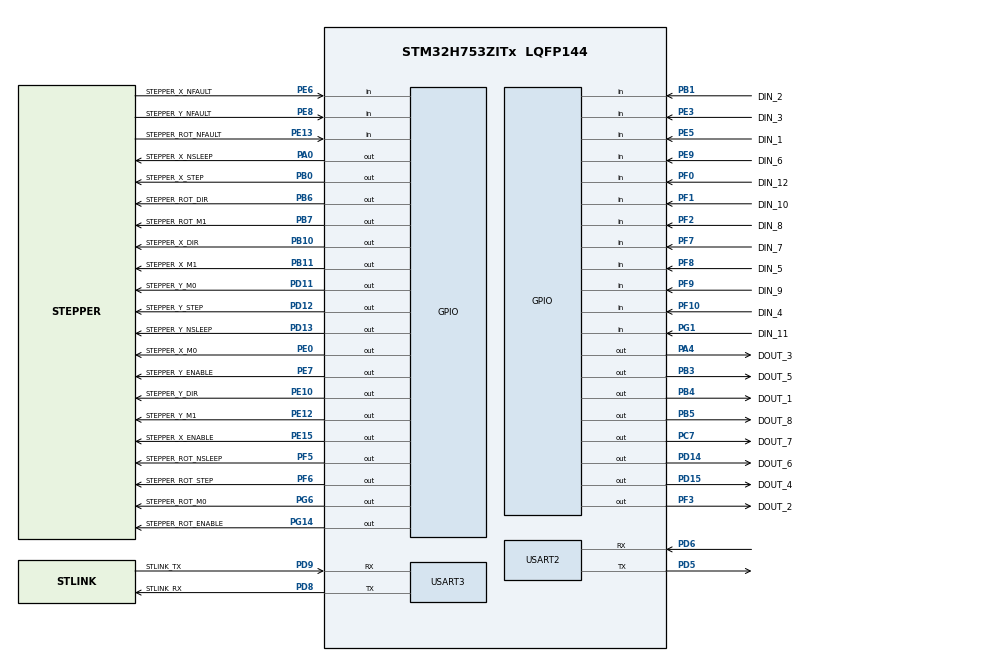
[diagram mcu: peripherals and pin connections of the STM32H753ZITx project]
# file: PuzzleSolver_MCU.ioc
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CORTEX_M7.CPU_DCache=Disabled
CORTEX_M7.CPU_ICache=Disabled
CORTEX_M7.MPU_Control=__NULL
CORTEX_M7.default_mode_Activation=1
Mcu.Family=STM32H7
Mcu.Name=STM32H753ZITx
Mcu.Package=LQFP144
NVIC.PriorityGroup=NVIC_PRIORITYGROUP_4
NVIC.TIM2_IRQn=true\:2\:0\:true\:false\:true\:true\:true\:true
NVIC.TIM3_IRQn=true\:0\:0\:false\:false\:true\:true\:true\:true
NVIC.USART2_IRQn=true\:0\:0\:false\:false\:true\:true\:true\:true
PA0.GPIO_Label=STEPPER_X_NSLEEP
PA0.PinState=GPIO_PIN_SET
PA0.Signal=GPIO_Output
PA4.GPIO_Label=DOUT_3
PA4.Signal=GPIO_Output
PB0.GPIO_Label=STEPPER_X_STEP
PB0.GPIO_Speed=GPIO_SPEED_FREQ_MEDIUM
PB0.Signal=GPIO_Output
PB1.GPIO_Label=DIN_2
PB1.Signal=GPIO_Input
PB10.GPIO_Label=STEPPER_X_DIR
PB10.GPIO_Speed=GPIO_SPEED_FREQ_MEDIUM
PB10.Signal=GPIO_Output
PB11.GPIO_Label=STEPPER_X_M1
PB11.GPIO_Speed=GPIO_SPEED_FREQ_MEDIUM
PB11.Signal=GPIO_Output
PB12.Signal=UART5_RX
PB13.Signal=UART5_TX
PB3\ (JTDO/TRACESWO).GPIO_Label=DOUT_5
PB3\ (JTDO/TRACESWO).Signal=GPIO_Output
PB4\ (NJTRST).GPIO_Label=DOUT_1
PB4\ (NJTRST).PinState=GPIO_PIN_SET
PB4\ (NJTRST).Signal=GPIO_Output
PB5.GPIO_Label=DOUT_8
PB5.Signal=GPIO_Output
PB6.GPIO_Label=STEPPER_ROT_DIR
PB6.GPIO_Speed=GPIO_SPEED_FREQ_MEDIUM
PB6.Signal=GPIO_Output
PB7.GPIO_Label=STEPPER_ROT_M1
PB7.GPIO_Speed=GPIO_SPEED_FREQ_MEDIUM
PB7.Signal=GPIO_Output
PC14-OSC32_IN\ (OSC32_IN).Signal=RCC_OSC32_IN
PC15-OSC32_OUT\ (OSC32_OUT).Signal=RCC_OSC32_OUT
PC7.GPIO_Label=DOUT_7
PC7.Signal=GPIO_Output
PD11.GPIO_Label=STEPPER_Y_M0
PD11.GPIO_Speed=GPIO_SPEED_FREQ_MEDIUM
PD11.Signal=GPIO_Output
PD12.GPIO_Label=STEPPER_Y_STEP
PD12.GPIO_Speed=GPIO_SPEED_FREQ_MEDIUM
PD12.Signal=GPIO_Output
PD13.GPIO_Label=STEPPER_Y_NSLEEP
PD13.PinState=GPIO_PIN_SET
PD13.Signal=GPIO_Output
PD14.GPIO_Label=DOUT_6
PD14.Signal=GPIO_Output
PD15.GPIO_Label=DOUT_4
PD15.Signal=GPIO_Output
PD5.Mode=Asynchronous
PD5.Signal=USART2_TX
PD6.Mode=Asynchronous
PD6.Signal=USART2_RX
PD8.GPIO_Label=STLINK_RX
PD8.Mode=Asynchronous
PD8.Signal=USART3_TX
PD9.GPIO_Label=STLINK_TX
PD9.Mode=Asynchronous
PD9.Signal=USART3_RX
PE0.GPIO_Label=STEPPER_X_M0
PE0.GPIO_Speed=GPIO_SPEED_FREQ_MEDIUM
PE0.Signal=GPIO_Output
PE10.GPIO_Label=STEPPER_Y_DIR
PE10.GPIO_Speed=GPIO_SPEED_FREQ_MEDIUM
PE10.Signal=GPIO_Output
PE12.GPIO_Label=STEPPER_Y_M1
PE12.GPIO_Speed=GPIO_SPEED_FREQ_MEDIUM
PE12.Signal=GPIO_Output
PE13.GPIO_Label=STEPPER_ROT_NFAULT
PE13.Signal=GPIO_Input
PE15.GPIO_Label=STEPPER_X_ENABLE
PE15.Signal=GPIO_Output
PE3.GPIO_Label=DIN_3
PE3.Signal=GPIO_Input
PE5.GPIO_Label=DIN_1
PE5.Signal=GPIO_Input
PE6.GPIO_Label=STEPPER_X_NFAULT
PE6.Signal=GPIO_Input
PE7.GPIO_Label=STEPPER_Y_ENABLE
PE7.Signal=GPIO_Output
PE8.GPIO_Label=STEPPER_Y_NFAULT
PE8.Signal=GPIO_Input
PE9.GPIO_Label=DIN_6
PE9.Signal=GPIO_Input
PF0.GPIO_Label=DIN_12
PF0.Signal=GPIO_Input
PF1.GPIO_Label=DIN_10
PF1.Signal=GPIO_Input
PF10.GPIO_Label=DIN_4
PF10.Signal=GPIO_Input
PF2.GPIO_Label=DIN_8
PF2.Signal=GPIO_Input
PF3.GPIO_Label=DOUT_2
PF3.PinState=GPIO_PIN_SET
PF3.Signal=GPIO_Output
PF5.GPIO_Label=STEPPER_ROT_NSLEEP
PF5.PinState=GPIO_PIN_SET
PF5.Signal=GPIO_Output
PF6.GPIO_Label=STEPPER_ROT_STEP
PF6.GPIO_Speed=GPIO_SPEED_FREQ_MEDIUM
PF6.Signal=GPIO_Output
PF7.GPIO_Label=DIN_7
PF7.Signal=GPIO_Input
PF8.GPIO_Label=DIN_5
PF8.Signal=GPIO_Input
PF9.GPIO_Label=DIN_9
PF9.Signal=GPIO_Input
PG1.GPIO_Label=DIN_11
PG1.Signal=GPIO_Input
PG14.GPIO_Label=STEPPER_ROT_ENABLE
PG14.Signal=GPIO_Output
PG6.GPIO_Label=STEPPER_ROT_M0
PG6.GPIO_Speed=GPIO_SPEED_FREQ_MEDIUM
PG6.Signal=GPIO_Output
PH0-OSC_IN\ (PH0).Mode=HSE-External-Oscillator
PH0-OSC_IN\ (PH0).Signal=RCC_OSC_IN
PH1-OSC_OUT\ (PH1).Mode=HSE-External-Oscillator
PH1-OSC_OUT\ (PH1).Signal=RCC_OSC_OUT
ProjectManager.HeapSize=0x200
ProjectManager.StackSize=0x400
ProjectManager.TargetToolchain=CMake
RCC.ADCFreq_Value=16125000
RCC.APB1Freq_Value=60000000
RCC.APB2Freq_Value=120000000
RCC.APB3Freq_Value=120000000
RCC.APB4Freq_Value=120000000
RCC.CortexFreq_Value=480000000
RCC.D1PPRE=RCC_APB3_DIV2
RCC.D2PPRE1=RCC_APB1_DIV4
RCC.D2PPRE2=RCC_APB2_DIV2
RCC.D3PPRE=RCC_APB4_DIV2
RCC.DIVM1=1
RCC.DIVN1=120
RCC.DIVQ1=4
RCC.HCLKFreq_Value=240000000
RCC.HPRE=RCC_HCLK_DIV2
RCC.HSE_VALUE=8000000
RCC.PLLSourceVirtual=RCC_PLLSOURCE_HSE
RCC.SYSCLKFreq_VALUE=480000000
RCC.SYSCLKSource=RCC_SYSCLKSOURCE_PLLCLK
RCC.USBFreq_Value=240000000
TIM2.AutoReloadPreload=TIM_AUTORELOAD_PRELOAD_ENABLE
TIM2.Period=9
TIM2.Prescaler=119
TIM3.Period=65535
TIM3.Prescaler=11999
USART2.VirtualMode-Asynchronous=VM_ASYNC
USART3.VirtualMode-Asynchronous=VM_ASYNC
VP_MEMORYMAP_VS_MEMORYMAP.Mode=CurAppReg
VP_TIM2_VS_ClockSourceINT.Mode=Internal
VP_TIM3_VS_ClockSourceINT.Mode=Internal
VP_TIM3_VS_OPM.Mode=OPM_bit
board=NUCLEO-H753ZI

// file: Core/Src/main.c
/* USER CODE BEGIN Header */
/**
 ******************************************************************************
 * @file           : main.c
 * @brief          : Main program body
 ******************************************************************************
 * @attention
 *
 * Copyright (c) 2026 STMicroelectronics.
 * All rights reserved.
 *
 * This software is licensed under terms that can be found in the LICENSE file
 * in the root directory of this software component.
 * If no LICENSE file comes with this software, it is provided AS-IS.
 *
 ******************************************************************************
 */
/* USER CODE END Header */
#include "main.h"
#include "tim.h"
#include "usart.h"
#include "gpio.h"

/* USER CODE BEGIN Includes */
#include "app.h"
#include "sys_init.h"

#include <stdbool.h>

/* USER CODE END Includes */

void SystemClock_Config(void);

int main(void)
{

  /* MCU Configuration--------------------------------------------------------*/

  /* Reset of all peripherals, Initializes the Flash interface and the Systick. */
  HAL_Init();

  /* Configure the system clock */
  SystemClock_Config();

  /* Initialize all configured peripherals */
  MX_GPIO_Init();
  MX_TIM2_Init();
  MX_TIM3_Init();
  MX_USART3_UART_Init();
  MX_USART2_UART_Init();
  /* USER CODE BEGIN 2 */

  HAL_TIM_Base_Init(&htim2);
  HAL_TIM_Base_Init(&htim3);

  Sys_Init();
  /* USER CODE END 2 */

  /* Infinite loop */
  while (1) {

    /* USER CODE BEGIN 3 */
    App_Run();
  }
  /* USER CODE END 3 */
}

void SystemClock_Config(void)
{
  RCC_OscInitTypeDef RCC_OscInitStruct = {0};
  RCC_ClkInitTypeDef RCC_ClkInitStruct = {0};

  /** Supply configuration update enable
  */
  HAL_PWREx_ConfigSupply(PWR_LDO_SUPPLY);

  /** Configure the main internal regulator output voltage
  */
  __HAL_PWR_VOLTAGESCALING_CONFIG(PWR_REGULATOR_VOLTAGE_SCALE0);

  while(!__HAL_PWR_GET_FLAG(PWR_FLAG_VOSRDY)) {}

  /** Initializes the RCC Oscillators according to the specified parameters
  * in the RCC_OscInitTypeDef structure.
  */
  RCC_OscInitStruct.OscillatorType = RCC_OSCILLATORTYPE_HSE;
  RCC_OscInitStruct.HSEState = RCC_HSE_ON;
  RCC_OscInitStruct.PLL.PLLState = RCC_PLL_ON;
  RCC_OscInitStruct.PLL.PLLSource = RCC_PLLSOURCE_HSE;
  RCC_OscInitStruct.PLL.PLLM = 1;
  RCC_OscInitStruct.PLL.PLLN = 120;
  RCC_OscInitStruct.PLL.PLLP = 2;
  RCC_OscInitStruct.PLL.PLLQ = 4;
  RCC_OscInitStruct.PLL.PLLR = 2;
  RCC_OscInitStruct.PLL.PLLRGE = RCC_PLL1VCIRANGE_3;
  RCC_OscInitStruct.PLL.PLLVCOSEL = RCC_PLL1VCOWIDE;
  RCC_OscInitStruct.PLL.PLLFRACN = 0;
  if (HAL_RCC_OscConfig(&RCC_OscInitStruct) != HAL_OK)
  {
    Error_Handler();
  }

  /** Initializes the CPU, AHB and APB buses clocks
  */
  RCC_ClkInitStruct.ClockType = RCC_CLOCKTYPE_HCLK|RCC_CLOCKTYPE_SYSCLK
                              |RCC_CLOCKTYPE_PCLK1|RCC_CLOCKTYPE_PCLK2
                              |RCC_CLOCKTYPE_D3PCLK1|RCC_CLOCKTYPE_D1PCLK1;
  RCC_ClkInitStruct.SYSCLKSource = RCC_SYSCLKSOURCE_PLLCLK;
  RCC_ClkInitStruct.SYSCLKDivider = RCC_SYSCLK_DIV1;
  RCC_ClkInitStruct.AHBCLKDivider = RCC_HCLK_DIV2;
  RCC_ClkInitStruct.APB3CLKDivider = RCC_APB3_DIV2;
  RCC_ClkInitStruct.APB1CLKDivider = RCC_APB1_DIV4;
  RCC_ClkInitStruct.APB2CLKDivider = RCC_APB2_DIV2;
  RCC_ClkInitStruct.APB4CLKDivider = RCC_APB4_DIV2;

  if (HAL_RCC_ClockConfig(&RCC_ClkInitStruct, FLASH_LATENCY_4) != HAL_OK)
  {
    Error_Handler();
  }
}

void Error_Handler(void)
{
  /* USER CODE BEGIN Error_Handler_Debug */
  /* User can add his own implementation to report the HAL error return state
   */
  __disable_irq();
  while (1) {
  }
  /* USER CODE END Error_Handler_Debug */
}
#ifdef USE_FULL_ASSERT
/**
  * @brief  Reports the name of the source file and the source line number
  *         where the assert_param error has occurred.
  * @param  file: pointer to the source file name
  * @param  line: assert_param error line source number
  * @retval None
  */
void assert_failed(uint8_t *file, uint32_t line)
{
  /* USER CODE BEGIN 6 */
  /* User can add his own implementation to report the file name and line
     number, ex: printf("Wrong parameters value: file %s on line %d\r\n",
     file, line) */
  /* USER CODE END 6 */
}
#endif /* USE_FULL_ASSERT */
